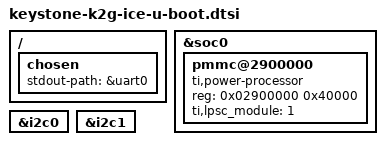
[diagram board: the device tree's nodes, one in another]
// SPDX-License-Identifier: GPL-2.0+
/*
 * Copyright (C) 2017 Texas Instruments Incorporated - https://www.ti.com/
 */

/{
	chosen {
		stdout-path = &uart0;
	};
};

&soc0 {
	bootph-all;

	pmmc@2900000 {
		bootph-all;
		compatible = "ti,power-processor";
		reg = <0x02900000 0x40000>;
		ti,lpsc_module = <1>;
	};
};

&i2c0 {
	status = "okay";
	bootph-all;
};

&i2c1 {
	status = "okay";
	bootph-all;
};
